# YTM32B1HA0 register map
Vendor: YTMicro; File version: 1.0
CPU: little endian, MPU, FPU, 2 interrupt priority bits
Registers are 32-bit, read-write, reset 0x0 unless marked. A register's access mark holds for its fields unless they carry their own. Offsets are from the block's base; [hi:lo] are bit positions; lines under a group give offsets from that group; {n}, {i} and the like mark numbered series; 'fields as' and 'values as' point back to an identical list; <NAME> marks a mode.

## ENET (part 1 of 10) — Ethernet Quality-of-Service
Base 0x401E4000; register names take the prefix ENET_
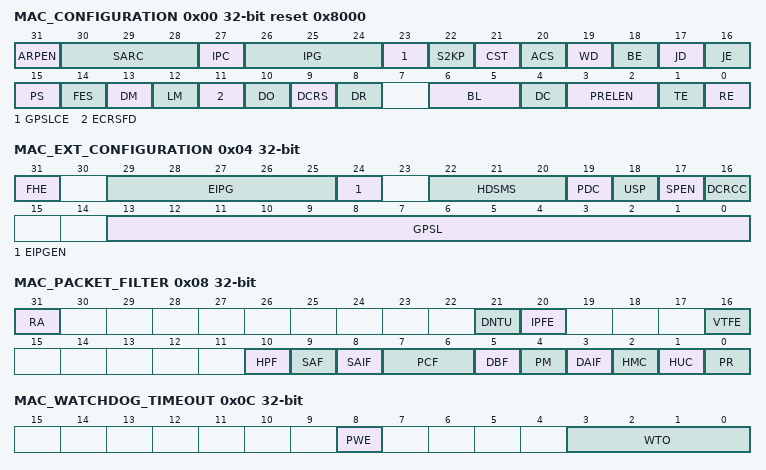
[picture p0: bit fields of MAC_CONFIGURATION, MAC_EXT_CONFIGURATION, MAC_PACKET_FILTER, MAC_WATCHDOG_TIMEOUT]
0x00 MAC_CONFIGURATION reset 0x8000
  [31] ARPEN — When this bit is set, the MAC can recognize an incoming ARP request packet and schedules the ARP packet for transmission. It forwards the ARP packet to the application and also indicate the events in the RxStatus. When this bit is reset, the MAC receiver does not recognize any ARP packet and indicates them as Type frame in the RxStatus. This bit is available only when the Enable IPv4 ARP Offload is selected.
    0=ARP Offload is disabled; 1=ARP Offload is enabled
  [30:28] SARC — This field controls the source address insertion or replacement for all transmitted packets. Bit 30 specifies which MAC Address register (0 or 1) is used for source address insertion or replacement based on the values of Bits[29:28]: 2'b0x: - The mti_sa_ctrl_i and ati_sa_ctrl_i input signals control the SA field generation. 2'b10: - If Bit 30 is set to 0, the MAC inserts the content of the MAC Address 0 registers in the SA field of all transmitted packets. - If Bit 30 is set to 1 and the Enable MAC Address Register 1 option is selected while configuring the core, the MAC inserts the content of the MAC Address 1 registers in the SA field of all transmitted packets. 2'b11: - If Bit 30 is set to 0, the MAC replaces the content of the MAC Address 0 registers in the SA field of all transmitted packets. - If Bit 30 is set to 1 and the MAC Address Register 1 is enabled, the MAC replaces the content of the MAC Address 1 registers in the SA field of all transmitted packets. Note: Changes to this field take effect only on the start of a packet. If you write to this register field when a packet is being transmitted, only the subsequent packet can use the updated value, that is, the current packet does not use the updated value.
    0=mti_sa_ctrl_i and ati_sa_ctrl_i input signals control the SA field generation; 2=Contents of MAC Addr-0 inserted in SA field; 3=Contents of MAC Addr-0 replaces SA field; 6=Contents of MAC Addr-1 inserted in SA field; 7=Contents of MAC Addr-1 replaces SA field
  [27] IPC — When set, this bit enables the IPv4 header checksum checking and IPv4 or IPv6 TCP, UDP, or ICMP payload checksum checking. When this bit is reset, the COE function in the receiver is disabled. The Layer 3 and Layer 4 Packet Filter and Enable Split Header features automatically selects the IPC Full Checksum Offload Engine on the Receive side. When any of these features are enabled, you must set the IPC bit.
    0=IP header/payload checksum checking is disabled; 1=IP header/payload checksum checking is enabled
  [26:24] IPG — These bits control the minimum IPG between packets during transmission. This range of minimum IPG is valid in full-duplex mode. In the half-duplex mode, the minimum IPG can be configured only for 64-bit times (IPG = 100). Lower values are not considered. When a JAM pattern is being transmitted because of backpressure activation, the MAC does not consider the minimum IPG. The above function (IPG less than 96 bit times) is valid only when EIPGEN bit in MAC_Ext_Configuration register is reset. When EIPGEN is set, then the minimum IPG (greater than 96 bit times) is controlled as per the description given in EIPG field in MAC_Ext_Configuration register.
    0=96 bit; 1=88 bit; 2=80 bit; 3=72 bit; 4=64 bit; 5=56 bit; 6=48 bit; 7=40 bit
  [23] GPSLCE — When this bit is set, the MAC considers the value in GPSL field in MAC_Ext_Configuration register to declare a received packet as Giant packet. This field must be programmed to more than 1,518 bytes. Otherwise, the MAC considers 1,518 bytes as giant packet limit. When this bit is reset, the MAC considers a received packet as Giant packet when its size is greater than 1,518 bytes (1522 bytes for tagged packet). The watchdog timeout limit, Jumbo Packet Enable and 2K Packet Enable have higher precedence over this bit, that is the MAC considers a received packet as Giant packet when its size is greater than 9,018 bytes (9,022 bytes for tagged packet) with Jumbo Packet Enabled and greater than 2,000 bytes with 2K Packet Enabled. The watchdog timeout, if enabled, terminates the received packet when watchdog limit is reached. Therefore, the programmed giant packet limit should be less than the watchdog limit to get the giant packet status.
    0=Giant Packet Size Limit Control is disabled; 1=Giant Packet Size Limit Control is enabled
  [22] S2KP — When this bit is set, the MAC considers all packets with up to 2,000 bytes length as normal packets. When the JE bit is not set, the MAC considers all received packets of size more than 2K bytes as Giant packets. When this bit is reset and the JE bit is not set, the MAC considers all received packets of size more than 1,518 bytes (1,522 bytes for tagged) as giant packets. For more information about how the setting of this bit and the JE bit impact the Giant packet status, see the Table, Gaint Packet Status based on S2KP and JE Bits. Note: When the JE bit is set, setting this bit has no effect on the giant packet status.
    0=Support upto 2K packet is disabled; 1=Support upto 2K packet is Enabled
  [21] CST — When this bit is set, the last four bytes (FCS) of all packets of Ether type (type field greater than 1,536) are stripped and dropped before forwarding the packet to the application. Note: For information about how the settings of the ACS bit and this bit impact the packet length, see the Table, Packet Length based on the CST and ACS Bits.
    0=CRC stripping for Type packets is disabled; 1=CRC stripping for Type packets is enabled
  [20] ACS — When this bit is set, the MAC strips the Pad or FCS field on the incoming packets only if the value of the length field is less than 1,536 bytes. All received packets with length field greater than or equal to 1,536 bytes are passed to the application without stripping the Pad or FCS field. When this bit is reset, the MAC passes all incoming packets to the application, without any modification. Note: For information about how the settings of CST bit and this bit impact the packet length, see the Table, Packet Length based on the CST and ACS Bit.
    0=Automatic Pad or CRC Stripping is disabled; 1=Automatic Pad or CRC Stripping is enabled
  [19] WD — When this bit is set, the MAC disables the watchdog timer on the receiver. The MAC can receive packets of up to 16,383 bytes. When this bit is reset, the MAC does not allow more than 2,048 bytes (10,240 if JE is set high) of the packet being received. The MAC cuts off any bytes received after 2,048 bytes.
    0=Watchdog is enabled; 1=Watchdog is disabled
  [18] BE — When this bit is set, the MAC allows packet bursting during transmission in the GMII half-duplex mode.
    0=Packet Burst is disabled; 1=Packet Burst is enabled
  [17] JD — When this bit is set, the MAC disables the jabber timer on the transmitter. The MAC can transfer packets of up to 16,383 bytes. When this bit is reset, if the application sends more than 2,048 bytes of data (10,240 if JE is set high) during transmission, the MAC does not send rest of the bytes in that packet.
    0=Jabber is enabled; 1=Jabber is disabled
  [16] JE — When this bit is set, the MAC allows jumbo packets of 9,018 bytes (9,022 bytes for VLAN tagged packets) without reporting a giant packet error in the Rx packet status.
    0=Jumbo Packet is disabled; 1=Jumbo Packet is enabled
  [15] PS — This bit selects the Ethernet line speed. This bit, along with Bit 14, selects the exact line speed. In the 10/100 Mbps-only (always 1) or 1000 Mbps-only (always 0) configurations, this bit is read-only (RO) with appropriate value. In default 10/100/1000 Mbps configurations, this bit is read-write (R/W). The mac_speed_o[1] signal reflects the value of this bit.
    0=For 1000 or 2500 Mbps operations; 1=For 10 or 100 Mbps operations
  [14] FES — This bit selects the speed mode. The mac_speed_o[0] signal reflects the value of this bit.
    0=10 Mbps when PS bit is 1 and 1 Gbps when PS bit is 0; 1=100 Mbps when PS bit is 1 and 2.5 Gbps when PS bit is 0
  [13] DM — When this bit is set, the MAC operates in the full-duplex mode in which it can transmit and receive simultaneously. This bit is RO with default value of 1'b1 in the full-duplex-only configurations.
    0=Half-duplex mode; 1=Full-duplex mode
  [12] LM — When this bit is set, the MAC operates in the loopback mode at GMII or MII. The (G)MII Rx clock input (clk_rx_i) is required for the loopback to work properly. This is because the Tx clock is not internally looped back.
    0=Loopback is disabled; 1=Loopback is enabled
  [11] ECRSFD — When this bit is set, the MAC transmitter checks the CRS signal before packet transmission in the full-duplex mode. The MAC starts the transmission only when the CRS signal is low. When this bit is reset, the MAC transmitter ignores the status of the CRS signal.
    0=ECRSFD is disabled; 1=ECRSFD is enabled
  [10] DO — When this bit is set, the MAC disables the reception of packets when the gmii_txen_o is asserted in the half-duplex mode. When this bit is reset, the MAC receives all packets given by the PHY. This bit is not applicable in the full-duplex mode.
    0=Enable Receive Own; 1=Disable Receive Own
  [9] DCRS — When this bit is set, the MAC transmitter ignores the (G)MII CRS signal during packet transmission in the half-duplex mode. As a result, no errors are generated because of Loss of Carrier or No Carrier during transmission. When this bit is reset, the MAC transmitter generates errors because of Carrier Sense. The MAC can even abort the transmission.
    0=Enable Carrier Sense During Transmission; 1=Disable Carrier Sense During Transmission
  [8] DR — When this bit is set, the MAC attempts only one transmission. When a collision occurs on the GMII or MII interface, the MAC ignores the current packet transmission and reports a Packet Abort with excessive collision error in the Tx packet status. When this bit is reset, the MAC retries based on the settings of the BL field. This bit is applicable only in the half-duplex mode.
    0=Enable Retry; 1=Disable Retry
  [6:5] BL — The back-off limit determines the random integer number (r) of slot time delays (4,096 bit times for 1000/2500 Mbps; 512 bit times for 10/100 Mbps) for which the MAC waits before rescheduling a transmission attempt during retries after a collision. n = retransmission attempt. The random integer r takes the value in the range 0 <= r < 2^k This bit is applicable only in the half-duplex mode.
    0=k = min(n,10); 1=k = min(n,8); 2=k = min(n,4); 3=k = min(n,1)
  [4] DC — When this bit is set, the deferral check function is enabled in the MAC. The MAC issues a Packet Abort status, along with the excessive deferral error bit set in the Tx packet status, when the Tx state machine is deferred for more than 24,288 bit times in 10 or 100 Mbps mode. If the MAC is configured for 1000/2500 Mbps operation, the threshold for deferral is 155,680 bits times. Deferral begins when the transmitter is ready to transmit, but it is prevented because of an active carrier sense signal (CRS) on GMII or MII. The defer time is not cumulative. For example, if the transmitter defers for 10,000 bit times because the CRS signal is active and the CRS signal becomes inactive, the transmitter transmits and collision happens. Because of collision, the transmitter needs to back off and then defer again after back off completion. In such a scenario, the deferral timer is reset to 0, and it is restarted. When this bit is reset, the deferral check function is disabled and the MAC defers until the CRS signal goes inactive. This bit is applicable only in the half-duplex mode.
    0=Deferral check function is disabled; 1=Deferral check function is enabled
  [3:2] PRELEN — These bits control the number of preamble bytes that are added to the beginning of every Tx packet. The preamble reduction occurs only when the MAC is operating in the full-duplex mode.
    0=7 bytes of preamble; 1=5 bytes of preamble; 2=3 bytes of preamble
  [1] TE — When this bit is set, the Tx state machine of the MAC is enabled for transmission on the GMII or MII interface. When this bit is reset, the MAC Tx state machine is disabled after it completes the transmission of the current packet. The Tx state machine does not transmit any more packets.
    0=Transmitter is disabled; 1=Transmitter is enabled
  [0] RE — When this bit is set, the Rx state machine of the MAC is enabled for receiving packets from the GMII or MII interface. When this bit is reset, the MAC Rx state machine is disabled after it completes the reception of the current packet. The Rx state machine does not receive any more packets from the GMII or MII interface.
    0=Receiver is disabled; 1=Receiver is enabled
0x04 MAC_EXT_CONFIGURATION — The MAC Extended Configuration Register establishes the operating mode of the MAC.
  [31] FHE — When this is set then it is expected that all the incoming packets from the Line to have 4B Flexible Header in the Rx path (except for the pause and PFC packets). Similarly, in the Tx path all the packets from application are expected to have 4B Flexible header. The position of the Flexible Header is always fixed at 12Bytes from the beginning of the packet (after MAC DA/SA).
    0=Flexible Header is disabled; 1=Flexible Header is enabled
  [29:25] EIPG — The value in this field is applicable when the EIPGEN bit is set. This field (as Most Significant bits), along with IPG field in MAC_Configuration register, gives the minimum IPG greater than 96 bit times in steps of 8 bit times: {EIPG, IPG} 8'h00 - 104 bit times 8'h01 - 112 bit times 8'h02 - 120 bit times ----------------------- 8'hFF - 2144 bit times
  [24] EIPGEN — When this bit is set, the MAC interprets EIPG field and IPG field in MAC_Configuration register together as minimum IPG greater than 96 bit times in steps of 8 bit times. When this bit is reset, the MAC ignores EIPG field and interprets IPG field in MAC_Configuration register as minimum IPG less than or equal to 96 bit times in steps of 8 bit times. Note: The extended Inter-Packet Gap feature must be enabled when operating in Full-Duplex mode only. There may be undesirable effects on back-pressure function and frame transmission if it is enabled in Half-Duplex mode.
    0=Extended Inter-Packet Gap is disabled; 1=Extended Inter-Packet Gap is enabled
  [22:20] HDSMS — These bits indicate the maximum header size allowed for splitting the header data in the received packet.
    0=Maximum Size for Splitting the Header Data is 64 bytes; 1=Maximum Size for Splitting the Header Data is 128 bytes; 2=Maximum Size for Splitting the Header Data is 256 bytes; 3=Maximum Size for Splitting the Header Data is 512 bytes; 4=Maximum Size for Splitting the Header Data is 1024 bytes
  [19] PDC — When this bit is set, the received packet with Multicast/Broadcast Destination address is routed to multiple Receive DMA Channels. The Receive DMA Channels is identified by the DCS field of MAC_Address(#i)_High register corresponding to the MAC Address register that matches the Multicast/Broadcast Destination address in the received packet. The DCS field is interpreted to be a one-hot value, each bit corresponding to the Receive DMA Channel. When this bit is reset, the received packet is routed to single Receive DMA Channel. The Receive DMA Channel is identified by the DCS field of MAC_Address(#i)_High register corresponding to the MAC Address register that matches the Destination address in the received packet. The DCS field is interpreted as a binary value.
    0=Packet Duplication Control is disabled; 1=Packet Duplication Control is enabled
  [18] USP — When this bit is set, the MAC detects the Slow Protocol packets with unicast address of the station specified in the MAC_Address0_High and MAC_Address0_Low registers. The MAC also detects the Slow Protocol packets with the Slow Protocols multicast address (01-80-C2-00-00-02). When this bit is reset, the MAC detects only Slow Protocol packets with the Slow Protocol multicast address specified in the IEEE 802.3-2015, Section 5.
    0=Unicast Slow Protocol Packet Detect is disabled; 1=Unicast Slow Protocol Packet Detect is enabled
  [17] SPEN — When this bit is set, MAC processes the Slow Protocol packets (Ether Type 0x8809) and provides the Rx status. The MAC discards the Slow Protocol packets with invalid sub-types. When this bit is reset, the MAC forwards all error-free Slow Protocol packets to the application. The MAC considers such packets as normal Type packets.
    0=Slow Protocol Detection is disabled; 1=Slow Protocol Detection is enabled
  [16] DCRCC — When this bit is set, the MAC receiver does not check the CRC field in the received packets. When this bit is reset, the MAC receiver always checks the CRC field in the received packets.
    0=CRC Check is enabled; 1=CRC Check is disabled
  [13:0] GPSL — If the received packet size is greater than the value programmed in this field in units of bytes, the MAC declares the received packet as Giant packet. The value programmed in this field must be greater than or equal to 1,518 bytes. Any other programmed value is considered as 1,518 bytes. For VLAN tagged packets, the MAC adds 4 bytes to the programmed value. When the Enable Double VLAN Processing option is selected, the MAC adds 8 bytes to the programmed value for double VLAN tagged packets. The value in this field is applicable when the GPSLCE bit is set in MAC_Configuration register.
0x08 MAC_PACKET_FILTER — The MAC Packet Filter register contains the filter controls for receiving packets. Some of the controls from this register go to the address check block of the MAC which performs the first level of address filtering. The second level of filtering is performed on the incoming packet based on other controls such as Pass Bad Packets and Pass Control Packets.
  [31] RA — When this bit is set, the MAC Receiver module passes all received packets to the application, irrespective of whether they pass the address filter or not. The result of the SA or DA filtering is updated (pass or fail) in the corresponding bit in the Rx Status Word. When this bit is reset, the Receiver module passes only those packets to the application that pass the SA or DA address filter.
    0=Receive All is disabled; 1=Receive All is enabled
  [21] DNTU — When this bit is set, the MAC drops the non-TCP or UDP over IP packets. The MAC forward only those packets that are processed by the Layer 4 filter. When this bit is reset, the MAC forwards all non-TCP or UDP over IP packets.
    0=Forward Non-TCP/UDP over IP Packets; 1=Drop Non-TCP/UDP over IP Packets
  [20] IPFE — When this bit is set, the MAC drops packets that do not match the enabled Layer 3 and Layer 4 filters. If Layer 3 or Layer 4 filters are not enabled for matching, this bit does not have any effect. When this bit is reset, the MAC forwards all packets irrespective of the match status of the Layer 3 and Layer 4 fields.
    0=Layer 3 and Layer 4 Filters are disabled; 1=Layer 3 and Layer 4 Filters are enabled
  [16] VTFE — When this bit is set, the MAC drops the VLAN tagged packets that do not match the VLAN Tag. When this bit is reset, the MAC forwards all packets irrespective of the match status of the VLAN Tag.
    0=VLAN Tag Filters are disabled; 1=VLAN Tag Filters are enabled
  [10] HPF — When this bit is set, the address filter passes a packet if it matches either the perfect filtering or hash filtering as set by the HMC or HUC bit. When this bit is reset and the HUC or HMC bit is set, the packet is passed only if it matches the Hash filter.
    0=Hash or Perfect Filter is disabled; 1=Hash or Perfect Filter is enabled
  [9] SAF — When this bit is set, the MAC compares the SA field of the received packets with the values programmed in the enabled SA registers. If the comparison fails, the MAC drops the packet. When this bit is reset, the MAC forwards the received packet to the application with updated SAF bit of the Rx Status depending on the SA address comparison. Note: According to the IEEE specification, Bit 47 of the SA is reserved. However, in DWC_ether_qos, the MAC compares all 48 bits. The software driver should take this into consideration while programming the MAC address registers for SA.
    0=Source Address Filter is disabled; 1=Source Address Filter is enabled
  [8] SAIF — When this bit is set, the Address Check block operates in the inverse filtering mode for SA address comparison. If the SA of a packet matches the values programmed in the SA registers, it is marked as failing the SA Address filter. When this bit is reset, if the SA of a packet does not match the values programmed in the SA registers, it is marked as failing the SA Address filter.
    0=Source Address Inverse Filtering is disabled; 1=Source Address Inverse Filtering is enabled
  [7:6] PCF — These bits control the forwarding of all control packets (including unicast and multicast Pause packets).
    0=MAC filters all control packets from reaching the application; 1=MAC forwards all control packets except Pause packets to the application even if they fail the Address filter; 2=MAC forwards all control packets to the application even if they fail the Address filter; 3=MAC forwards the control packets that pass the Address filter
  [5] DBF — When this bit is set, the AFM module blocks all incoming broadcast packets. In addition, it overrides all other filter settings. When this bit is reset, the AFM module passes all received broadcast packets.
    0=Broadcast Packets are enabled; 1=Broadcast Packets are disabled
  [4] PM — When this bit is set, it indicates that all received packets with a multicast destination address (first bit in the destination address field is '1') are passed. When this bit is reset, filtering of multicast packet depends on HMC bit.
    0=Pass All Multicast is disabled; 1=Pass All Multicast is enabled
  [3] DAIF — When this bit is set, the Address Check block operates in inverse filtering mode for the DA address comparison for both unicast and multicast packets. When this bit is reset, normal filtering of packets is performed.
    0=DA Inverse Filtering is disabled; 1=DA Inverse Filtering is enabled
  [2] HMC — When this bit is set, the MAC performs the destination address filtering of received multicast packets according to the hash table. When this bit is reset, the MAC performs the perfect destination address filtering for multicast packets, that is, it compares the DA field with the values programmed in DA registers.
    0=Hash Multicast is disabled; 1=Hash Multicast is enabled
  [1] HUC — When this bit is set, the MAC performs the destination address filtering of unicast packets according to the hash table. When this bit is reset, the MAC performs a perfect destination address filtering for unicast packets, that is, it compares the DA field with the values programmed in DA registers.
    0=Hash Unicast is disabled; 1=Hash Unicast is enabled
  [0] PR — When this bit is set, the Address Filtering module passes all incoming packets irrespective of the destination or source address. The SA or DA Filter Fails status bits of the Rx Status Word are always cleared when PR is set.
    0=Promiscuous Mode is disabled; 1=Promiscuous Mode is enabled
0x0C MAC_WATCHDOG_TIMEOUT — The Watchdog Timeout register controls the watchdog timeout for received packets.
  [8] PWE — When this bit is set and the WD bit of the MAC_Configuration register is reset, the WTO field is used as watchdog timeout for a received packet. When this bit is cleared, the watchdog timeout for a received packet is controlled by setting of WD and JE bits in MAC_Configuration register.
    0=Programmable Watchdog is disabled; 1=Programmable Watchdog is enabled
  [3:0] WTO — When the PWE bit is set and the WD bit of the MAC_Configuration register is reset, this field is used as watchdog timeout for a received packet. If the length of a received packet exceeds the value of this field, such packet is terminated and declared as an error packet. Note: When the PWE bit is set, the value in this field should be more than 1,522 (0x05F2). Otherwise, the IEEE 802.3-specified valid tagged packets are declared as error packets and then dropped.
    {v}={v+2}KB (v=0..13); 14=16383 Bytes
{0x10+4i} MAC_HASH_TABLE_REG{i} (i=0..7) — The Hash Table Register contains the 64 bits of the hash table, when the width of the hash table is 128 or 256 bits. You can specify the width of the hash table by using the Hash Table Size option in coreConsultant. The Hash table is used for group address filtering. For hash filtering, the content of the destination address in the incoming packet is passed through the CRC logic and the upper six (seven in 128-bit Hash or eight in 256-bit Hash) bits of the CRC register are used to index the content of the Hash table. The most significant bits determines the register to be used (Hash Table Register X), and the least significant five bits determine the bit within the register. For example, a hash value of 6'b100000 (in 64-bit Hash) selects Bit 0 of the Hash Table Register 1, a value of 7b'1110000 (in 128-bit Hash) selects Bit 16 of the Hash Table Register 3 and a value of 8b'10111111 (in 256-bit Hash) selects Bit 31 of the Hash Table Register 5. The hash value of the destination address is calculated in the following way: - Calculate the 32-bit CRC for the DA (See IEEE 802.3, Section 3.2.8 for the steps to calculate CRC32). - Perform bitwise reversal for the value obtained in Step 1. - Take the upper 6 (or 7 or 8) bits from the value obtained in Step 2. If the corresponding bit value of the register is 1'b1, the packet is accepted. Otherwise, it is rejected. If the PM bit is set in MAC_Packet_Filter, all multicast packets are accepted regardless of the multicast hash values. If the Hash Table register is configured to be double-synchronized to the (G)MII clock domain, the synchronization is triggered only when Bits[31:24] (in little-endian mode) or Bits[7:0] (in big-endian mode) of the Hash Table Register X registers are written. If double-synchronization is enabled, consecutive writes to this register should be performed after at least four clock cycles in the destination clock domain.
  [31:0] HT
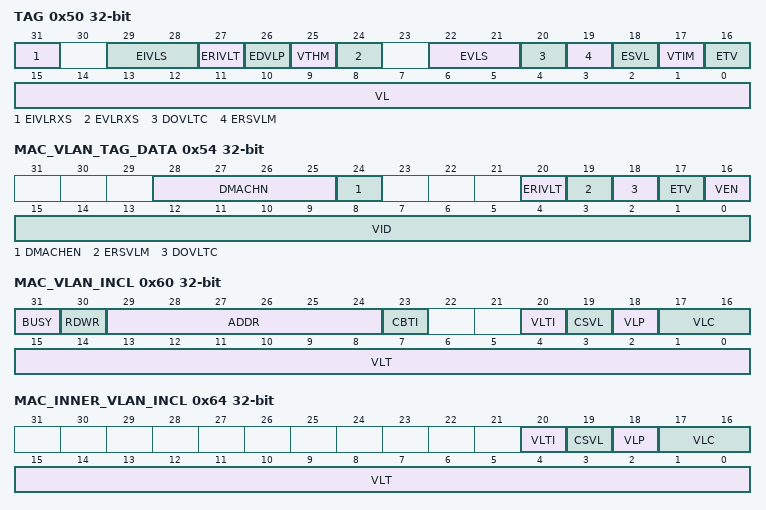
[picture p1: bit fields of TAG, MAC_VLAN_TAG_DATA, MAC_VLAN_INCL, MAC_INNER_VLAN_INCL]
0x50 TAG — The VLAN Tag register identifies the IEEE 802.1Q VLAN type packets.
  [31] EIVLRXS — When this bit is set, the MAC provides the inner VLAN Tag in the Rx status. When this bit is reset, the MAC does not provide the inner VLAN Tag in Rx status.
    0=Inner VLAN Tag in Rx status is disabled; 1=Inner VLAN Tag in Rx status is enabled
  [29:28] EIVLS — This field indicates the stripping operation on inner VLAN Tag in received packet.
    0=Do not strip; 1=Strip if VLAN filter passes; 2=Strip if VLAN filter fails; 3=Always strip
  [27] ERIVLT — When this bit and the EDVLP field are set, the MAC receiver enables operation on the inner VLAN Tag (if present). When this bit is reset, the MAC receiver enables operation on the outer VLAN Tag (if present). The ERSVLM bit determines which VLAN type is enabled for filtering or matching.
    0=Inner VLAN tag is disabled; 1=Inner VLAN Tag is enabled
  [26] EDVLP — When this bit is set, the MAC enables processing of up to two VLAN Tags on Tx and Rx (if present). When this bit is reset, the MAC enables processing of up to one VLAN Tag on Tx and Rx (if present).
    0=Double VLAN processing is disabled; 1=Double VLAN processing is enabled
  [25] VTHM — When this bit is set, the most significant four bits of CRC of VLAN Tag (ones-complement of most significant four bits of CRC of VLAN Tag when ETV bit is reset) are used to index the content of the MAC_VLAN_Hash_Table register. A value of 1 in the VLAN Hash Table register, corresponding to the index, indicates that the packet matched the VLAN hash table. When the ETV bit is set, the CRC of the 12-bit VLAN Identifier (VID) is used for comparison. When the ETV bit is reset, the ones-complement of the CRC of the 16-bit VLAN tag is used for comparison. When this bit is reset, the VLAN Hash Match operation is not performed.
    0=VLAN Hash Match operation is disabled; 1=VLAN Hash Match operation is enabled
  [24] EVLRXS — When this bit is set, MAC provides the outer VLAN Tag in the Rx status. When this bit is reset, the MAC does not provide the outer VLAN Tag in Rx status.
    0=VLAN Tag in Rx status is disabled; 1=VLAN Tag in Rx status is disabled
  [22:21] EVLS — This field indicates the stripping operation on the outer VLAN Tag in received packet.
    values as EIVLS
  [20] DOVLTC — When this bit is set, the MAC does not check whether the VLAN Tag specified by the ERIVLT bit is of type S-VLAN or C-VLAN. When this bit is reset, the MAC filters or matches the VLAN Tag specified by the ERIVLT bit only when VLAN Tag type is similar to the one specified by the ERSVLM bit.
    0=VLAN Type Check is enabled; 1=VLAN Type Check is disabled
  [19] ERSVLM — When this bit is set, the MAC receiver enables filtering or matching for S-VLAN (Type = 0x88A8) packets. When this bit is reset, the MAC receiver enables filtering or matching for C-VLAN (Type = 0x8100) packets. The ERIVLT bit determines the VLAN tag position considered for filtering or matching.
    0=Receive S-VLAN Match is disabled; 1=Receive S-VLAN Match is enabled
  [18] ESVL — When this bit is set, the MAC transmitter and receiver consider the S-VLAN packets (Type = 0x88A8) as valid VLAN tagged packets.
    0=S-VLAN is disabled; 1=S-VLAN is enabled
  [17] VTIM — When this bit is set, this bit enables the VLAN Tag inverse matching. The packets without matching VLAN Tag are marked as matched. When reset, this bit enables the VLAN Tag perfect matching. The packets with matched VLAN Tag are marked as matched.
    0=VLAN Tag Inverse Match is disabled; 1=VLAN Tag Inverse Match is enabled
  [16] ETV — When this bit is set, a 12-bit VLAN identifier is used for comparing and filtering instead of the complete 16-bit VLAN tag. Bits[11:0] of VLAN tag are compared with the corresponding field in the received VLAN-tagged packet. Similarly, when enabled, only 12 bits of the VLAN tag in the received packet are used for hash-based VLAN filtering. When this bit is reset, all 16 bits of the 15th and 16th bytes of the received VLAN packet are used for comparison and VLAN hash filtering.
    0=12-Bit VLAN Tag Comparison is disabled; 1=12-Bit VLAN Tag Comparison is enabled
  [15:0] VL — This field contains the 802.1Q VLAN tag to identify the VLAN packets. This VLAN tag identifier is compared to the 15th and 16th bytes of the packets being received for VLAN packets. The following list describes the bits of this field: - Bits[15:13]: User Priority - Bit 12: Canonical Format Indicator (CFI) or Drop Eligible Indicator (DEI) - Bits[11:0]: VLAN Identifier (VID) field of VLAN tag When the ETV bit is set, only the VID is used for comparison. If this field ([11:0] if ETV is set) is all zeros, the MAC does not check the 15th and 16th bytes for VLAN tag comparison and declares all packets with Type field value of 0x8100 or 0x88a8 as VLAN packets.
0x54 MAC_VLAN_TAG_DATA — This register holds the read/write data for Indirect Access of the Per VLAN Tag registers. During the read access, this field contains valid read data only after the OB bit is reset. During the write access, this field should be valid prior to setting the OB bit in the MAC_VLAN_Tag_Ctrl Register.
  [28:25] DMACHN — The DMA Channel number to which the VLAN Tagged Frame is to be routed if it passes this VLAN Tag Filter is programmed in this field. If the Routing based on VLAN Tag Filter is not necessary, this field need not be programmed.
  [24] DMACHEN — This bit is the Enable for the DMA Channel Number value programmed in the field DMACH. When this bit is reset, the Routing does not occur based on VLAN Filter result. The frame is routed based on DA Based DMA Channel Routing.
    0=DMA Channel Number is disabled; 1=DMA Channel Number is enabled
  [20] ERIVLT — This bit is valid only when VLAN Tag Enable of the Filter is set. When this bit and the EDVLP field are set, the MAC receiver enables operation on the inner VLAN Tag (if present). When this bit is reset, the MAC receiver enables operation on the outer VLAN Tag (if present).
    0=Inner VLAN Tag Comparison is disabled; 1=Inner VLAN Tag Comparison is enabled
  [19] ERSVLM — This bit is valid only when VLAN Tag Enable of the Filter is set. When this bit is set, the MAC receiver enables filtering or matching for S-VLAN (Type = 0x88A8) packets. When this bit is reset, the MAC receiver enables filtering or matching for C-VLAN (Type = 0x8100) packets.
    values as TAG.ERSVLM
  [18] DOVLTC — This bit is valid only when VLAN Tag Enable of the Filter is set. When this bit is set, the MAC does not check whether the VLAN Tag specified by the Enable Inner VLAN Tag Comparison bit is of type S-VLAN or C-VLAN. When this bit is reset, the MAC filters or matches the VLAN Tag specified by the Enable Inner VLAN Tag Comparison bit only when VLAN Tag type is similar to the one specified by the Enable S-VLAN Match for received Frames bit.
    0=VLAN Type Comparison is disabled; 1=VLAN Type Comparison is enabled
  [17] ETV — This bit is valid only when VEN of the Filter is set. When this bit is set, a 12-bit VLAN identifier is used for comparing and filtering instead of the complete 16-bit VLAN tag. Bits [11:0] of VLAN tag are compared with the corresponding field in the received VLAN-tagged packet.
    0=16 bit VLAN comparison; 1=12 bit VLAN comparison
  [16] VEN — This bit is used to enable or disable the VLAN Tag. When this bit is set, the MAC compares the VLAN Tag of received packet with the VLAN Tag ID. When this bit is reset, no comparison is performed irrespective of the programming of the other fields.
    0=VLAN Tag is disabled; 1=VLAN Tag is enabled
  [15:0] VID — This field holds the VLAN Tag value which is used by the MAC for perfect comparison. It is valid when VLAN Tag Enable is set.
0x58 MAC_VLAN_HASH_TABLE — When VTHM bit of the MAC_VLAN_Tag register is set, the 16-bit VLAN Hash Table register is used for group address filtering based on the VLAN tag. For hash filtering, the content of the 16-bit VLAN tag or 12-bit VLAN ID (based on the ETV bit of MAC_VLAN_Tag Register) in the incoming packet is passed through the CRC logic. When ETV bit of MAC_VLAN_Tag register is set, the upper four bits of the calculated CRC are used to index the contents of the VLAN Hash table. When ETV bit of MAC_VLAN_Tag register is reset, the ones-complement of upper four bits of the calculated CRC are used to index the contents of the VLAN Hash table. For example, when ETV bit is set a hash value of 4b'1000 selects Bit 8 of the VLAN Hash table, whereas when ETV bit is reset a hash value of 4b'1000 selects Bit 7 of the VLAN Hash table. The hash value of the destination address is calculated in the following way: - Calculate the 32-bit CRC for the VLAN tag or ID (For steps to calculate CRC32, see Section 3.2.8 of IEEE 802.3). - Perform bitwise reversal for the value obtained in step 1. - Take the upper four bits from the value obtained in step 2. If the VLAN hash Table register is configured to be double-synchronized to the (G)MII clock domain, the synchronization is triggered only when Bits[15:8] (in little-endian mode) or Bits[7:0] (in big-endian mode) of this register are written. - If double-synchronization is enabled, consecutive writes to this register should be performed after at least four clock cycles in the destination clock domain.
  [15:0] VLHT — This field contains the 16-bit VLAN Hash Table.
0x60 MAC_VLAN_INCL — The VLAN Tag Inclusion or Replacement register contains the VLAN tag for insertion or replacement in the Transmit packets. It also contains the VLAN tag insertion controls.
  [31] BUSY — This bit indicates the status of the read/write operation of indirect access to the queue/channel specific VLAN inclusion register. For write operation write to a register is complete when this bit is reset. For read operation the read data is valid when the bit is reset. The application must make sure that this bit is reset before attempting subsequent access to this register.
    0=Busy status not detected; 1=Busy status detected
  [30] RDWR — This bit controls the read or write operation for indirectly accessing the queue/channel specific VLAN Inclusion register. When set indicates write operation and when reset indicates read operation. This does not have any effect when CBTI is reset.
    0=Read operation of indirect access; 1=Write operation of indirect access
  [29:24] ADDR — This field selects one of the queue/channel specific VLAN Inclusion register for read/write access. This does not have any effect when CBTI is reset.
  [23] CBTI — When this bit is set, outer VLAN tag is inserted for every packets transmitted by the MAC. The tag value is taken from the queue/channel specific VLAN tag register. The VLTI, VLP, VLC, and VLT fields of this register are ignored when this bit is set. When this bit is set, a write operation to byte 3 of this register initiates the read/write access to the indirect register. When reset, outer VLAN operation is based on the setting of VLTI, VLP, VLC and VLT fields of this register.
    0=Channel based tag insertion is disabled; 1=Channel based tag insertion is enabled
  [20] VLTI — When this bit is set, it indicates that the VLAN tag to be inserted or replaced in Tx packet should be taken from the following: ■ The mti_vlan_tag_i signal in EQOS-CORE configurations ■ The control word in EQOS-MTL configurations ■ The Tx descriptor in EQOS-AHB, EQOS-AXI, or EQOS-DMA configurations
    0=VLAN Tag Input is disabled; 1=VLAN Tag Input is enabled
  [19] CSVL — When this bit is set, S-VLAN type (0x88A8) is inserted or replaced in the 13th and 14th bytes of transmitted packets. When this bit is reset, C-VLAN type (0x8100) is inserted or replaced in the 13th and 14th bytes of transmitted packets.
    0=C-VLAN type (0x8100) is inserted or replaced; 1=S-VLAN type (0x88A8) is inserted or replaced
  [18] VLP — When this bit is set, the control bits[17:16] are used for VLAN deletion, insertion, or replacement. When this bit is reset, the mti_vlan_ctrl_i control input is used and bits[17:16] are ignored.
    0=VLAN Priority Control is disabled; 1=VLAN Priority Control is enabled
  [17:16] VLC — ■ 2'b00: No VLAN tag deletion, insertion, or replacement ■ 2'b01: VLAN tag deletion The MAC removes the VLAN type (bytes 13 and 14) and VLAN tag (bytes 15 and 16) of all transmitted packets with VLAN tags. ■ 2'b10: VLAN tag insertion The MAC inserts VLT in bytes 15 and 16 of the packet after inserting the Type value (0x8100 or 0x88a8) in bytes 13 and 14. This operation is performed on all transmitted packets, irrespective of whether they already have a VLAN tag. ■ 2'b11: VLAN tag replacement The MAC replaces VLT in bytes 15 and 16 of all VLAN-type transmitted packets (Bytes 13 and 14 are 0x8100 or 0x88a8). Note: Changes to this field take effect only on the start of a packet. If you write this register field when a packet is being transmitted, only the subsequent packet can use the updated value, that is, the current packet does not use the updated value.
    0=No VLAN tag deletion, insertion, or replacement; 1=VLAN tag deletion; 2=VLAN tag insertion; 3=VLAN tag replacement
  [15:0] VLT — This field contains the value of the VLAN tag to be inserted or replaced. The value must only be changed when the transmit lines are inactive or during the initialization phase. Bits[15:13] are the User Priority field, Bit 12 is the CFI/DEI field, and Bits[11:0] are the VID field in the VLAN tag. The following list describes the bits of this field: ■ Bits[15:13]: User Priority ■ Bit 12: Canonical Format Indicator (CFI) or Drop Eligible Indicator (DEI) ■ Bits[11:0]: VLAN Identifier (VID) field of VLAN tag
0x64 MAC_INNER_VLAN_INCL — The Inner VLAN Tag Inclusion or Replacement register contains the inner VLAN tag to be inserted or replaced in the Transmit packet. It also contains the inner VLAN tag insertion controls.
  [20] VLTI — When this bit is set, it indicates that the VLAN tag to be inserted or replaced in Tx packet should be taken from the following: ■ The mti_vlan_tag_i signal in EQOS-CORE configurations ■ The control word in EQOS-MTL configurations ■ The Tx descriptor in EQOS-AHB, EQOS-AXI, or EQOS-DMA configurations
    0=VLAN Tag Input is disabled; 1=VLAN Tag Input is enabled
  [19] CSVL — When this bit is set, S-VLAN type (0x88A8) is inserted or replaced in the 13th and 14th bytes of transmitted packets. When this bit is reset, C-VLAN type (0x8100) is inserted or replaced in the 13th and 14th bytes of transmitted packets.
    values as MAC_VLAN_INCL.CSVL
  [18] VLP — When this bit is set, the control bits[17:16] are used for VLAN deletion, insertion, or replacement. When this bit is reset, the mti_vlan_ctrl_i control input is used and bits[17:16] are ignored.
    values as MAC_VLAN_INCL.VLP
  [17:16] VLC — ■ 2'b00: No VLAN tag deletion, insertion, or replacement ■ 2'b01: VLAN tag deletion The MAC removes the VLAN type (bytes 13 and 14) and VLAN tag (bytes 15 and 16) of all transmitted packets with VLAN tags. ■ 2'b10: VLAN tag insertion The MAC inserts VLT in bytes 15 and 16 of the packet after inserting the Type value (0x8100 or 0x88a8) in bytes 13 and 14. This operation is performed on all transmitted packets, irrespective of whether they already have a VLAN tag. ■ 2'b11: VLAN tag replacement The MAC replaces VLT in bytes 15 and 16 of all VLAN-type transmitted packets (Bytes 13 and 14 are 0x8100 or 0x88a8). Note: Changes to this field take effect only on the start of a packet. If you write this register field when a packet is being transmitted, only the subsequent packet can use the updated value, that is, the current packet does not use the updated value.
    values as MAC_VLAN_INCL.VLC
  [15:0] VLT — This field contains the value of the VLAN tag to be inserted or replaced. The value must only be changed when the transmit lines are inactive or during the initialization phase. Bits[15:13] are the User Priority field, Bit 12 is the CFI/DEI field, and Bits[11:0] are the VID field in the VLAN tag. The following list describes the bits of this field: ■ Bits[15:13]: User Priority ■ Bit 12: Canonical Format Indicator (CFI) or Drop Eligible Indicator (DEI) ■ Bits[11:0]: VLAN Identifier (VID) field of VLAN tag
